VERSION ""

NS_ :

BS_:

BU_:

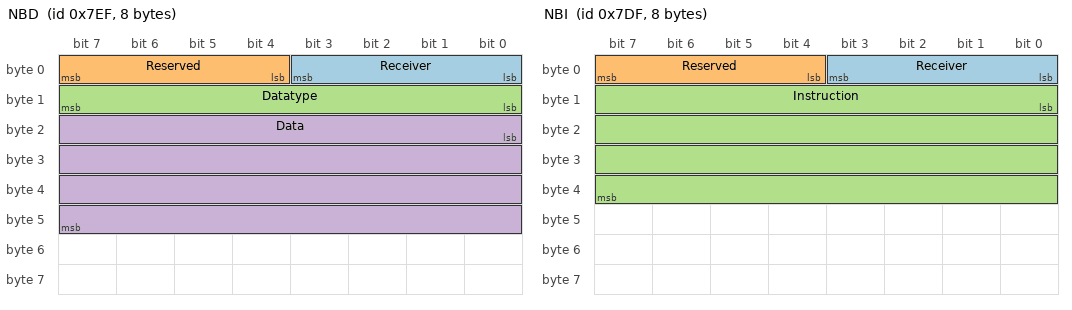
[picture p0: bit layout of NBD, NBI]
BO_ 2031 NBD: 8 Broadcast
	SG_ Receiver : 0|4@1+ (1,0) [0|0] "" Broadcast
	SG_ Reserved : 4|4@1+ (1,0) [0|0] "" Broadcast
	SG_ Datatype : 8|8@1+ (1,0) [0|0] "" Broadcast
	SG_ Data : 16|32@1+ (1,0) [0|0] "" Vector__XXX

BO_ 2015 NBI: 8 Broadcast
	SG_ Receiver : 0|4@1+ (1,0) [0|0] "" Broadcast
	SG_ Reserved : 4|4@1+ (1,0) [0|0] "" Broadcast
	SG_ Instruction : 8|32@1+ (1,0) [0|0] "" Broadcast

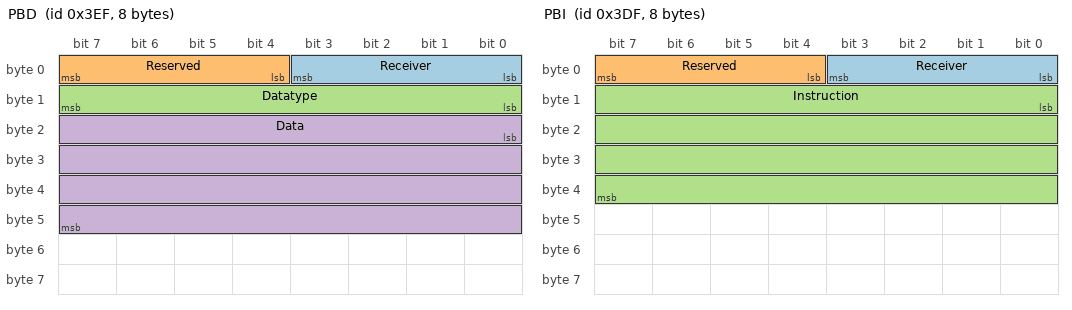
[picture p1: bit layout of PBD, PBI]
BO_ 1007 PBD: 8 Broadcast
	SG_ Receiver : 0|4@1+ (1,0) [0|0] "" Broadcast
	SG_ Reserved : 4|4@1+ (1,0) [0|0] "" Broadcast
	SG_ Datatype : 8|8@1+ (1,0) [0|0] "" Broadcast
	SG_ Data : 16|32@1+ (1,0) [0|0] "" Vector__XXX

BO_ 991 PBI: 8 Broadcast
	SG_ Receiver : 0|4@1+ (1,0) [0|0] "" Broadcast
	SG_ Reserved : 4|4@1+ (1,0) [0|0] "" Broadcast
	SG_ Instruction : 8|32@1+ (1,0) [0|0] "" Broadcast

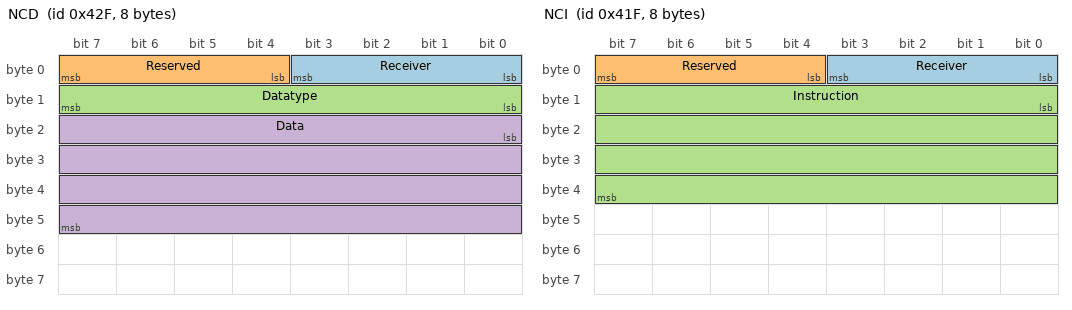
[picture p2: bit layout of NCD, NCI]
BO_ 1071 NCD: 8 CockpitECU
	SG_ Receiver : 0|4@1+ (1,0) [0|0] "" CockpitECU
	SG_ Reserved : 4|4@1+ (1,0) [0|0] "" CockpitECU
	SG_ Datatype : 8|8@1+ (1,0) [0|0] "" CockpitECU
	SG_ Data : 16|32@1+ (1,0) [0|0] "" Vector__XXX

BO_ 1055 NCI: 8 CockpitECU
	SG_ Receiver : 0|4@1+ (1,0) [0|0] "" CockpitECU
	SG_ Reserved : 4|4@1+ (1,0) [0|0] "" CockpitECU
	SG_ Instruction : 8|32@1+ (1,0) [0|0] "" CockpitECU

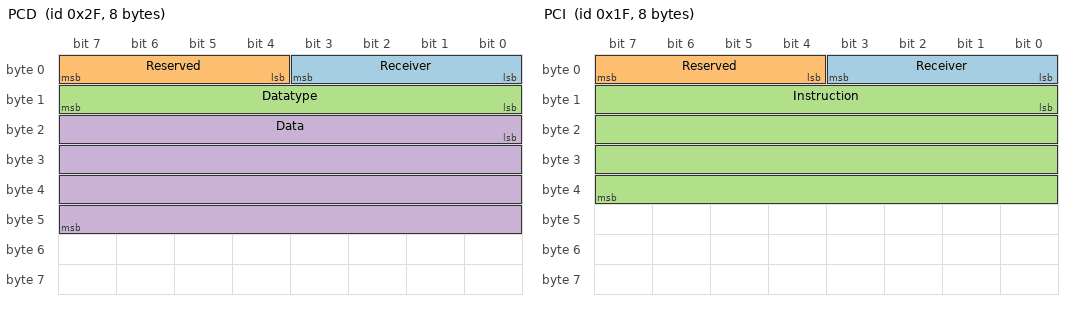
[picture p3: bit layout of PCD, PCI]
BO_ 47 PCD: 8 CockpitECU
	SG_ Receiver : 0|4@1+ (1,0) [0|0] "" CockpitECU
	SG_ Reserved : 4|4@1+ (1,0) [0|0] "" CockpitECU
	SG_ Datatype : 8|8@1+ (1,0) [0|0] "" CockpitECU
	SG_ Data : 16|32@1+ (1,0) [0|0] "" Vector__XXX

BO_ 31 PCI: 8 CockpitECU
	SG_ Receiver : 0|4@1+ (1,0) [0|0] "" CockpitECU
	SG_ Reserved : 4|4@1+ (1,0) [0|0] "" CockpitECU
	SG_ Instruction : 8|32@1+ (1,0) [0|0] "" CockpitECU

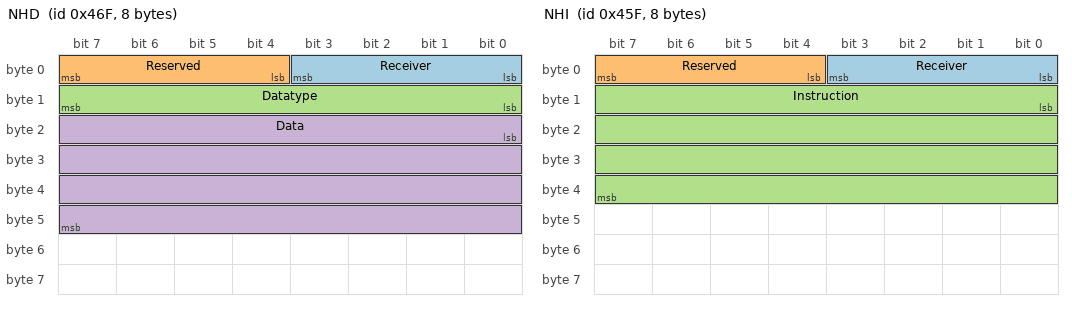
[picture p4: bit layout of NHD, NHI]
BO_ 1135 NHD: 8 HydrogenECU
	SG_ Receiver : 0|4@1+ (1,0) [0|0] "" HydrogenECU
	SG_ Reserved : 4|4@1+ (1,0) [0|0] "" HydrogenECU
	SG_ Datatype : 8|8@1+ (1,0) [0|0] "" HydrogenECU
	SG_ Data : 16|32@1+ (1,0) [0|0] "" Vector__XXX

BO_ 1119 NHI: 8 HydrogenECU
	SG_ Receiver : 0|4@1+ (1,0) [0|0] "" HydrogenECU
	SG_ Reserved : 4|4@1+ (1,0) [0|0] "" HydrogenECU
	SG_ Instruction : 8|32@1+ (1,0) [0|0] "" HydrogenECU

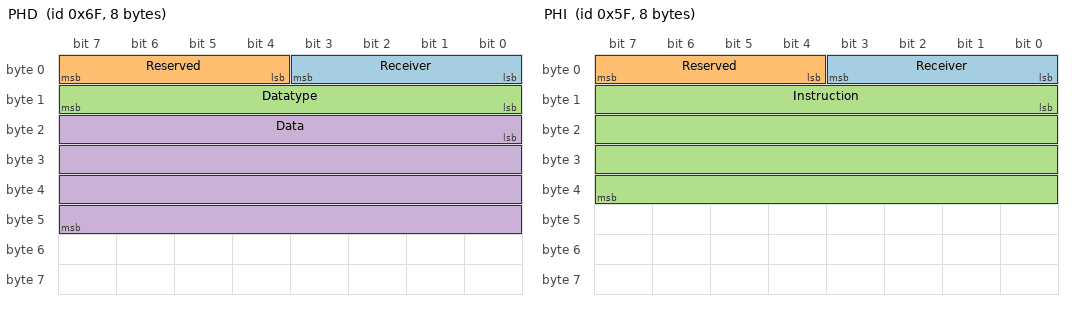
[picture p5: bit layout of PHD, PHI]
BO_ 111 PHD: 8 HydrogenECU
	SG_ Receiver : 0|4@1+ (1,0) [0|0] "" HydrogenECU
	SG_ Reserved : 4|4@1+ (1,0) [0|0] "" HydrogenECU
	SG_ Datatype : 8|8@1+ (1,0) [0|0] "" HydrogenECU
	SG_ Data : 16|32@1+ (1,0) [0|0] "" Vector__XXX

BO_ 95 PHI: 8 HydrogenECU
	SG_ Receiver : 0|4@1+ (1,0) [0|0] "" HydrogenECU
	SG_ Reserved : 4|4@1+ (1,0) [0|0] "" HydrogenECU
	SG_ Instruction : 8|32@1+ (1,0) [0|0] "" HydrogenECU

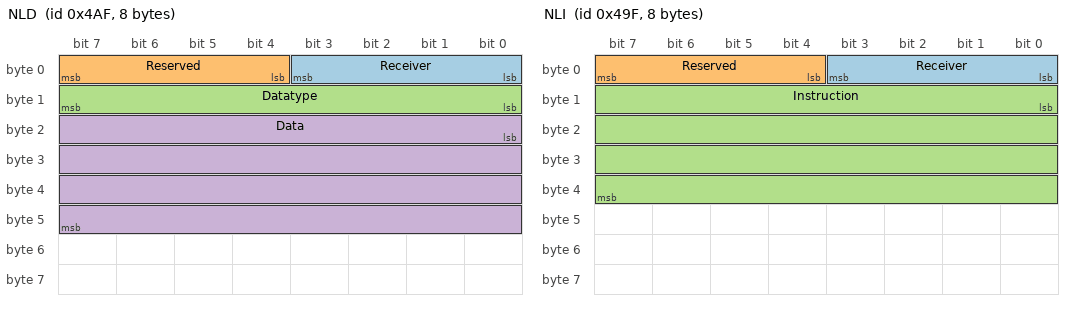
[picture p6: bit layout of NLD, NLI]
BO_ 1199 NLD: 8 LowPowerECU
	SG_ Receiver : 0|4@1+ (1,0) [0|0] "" LowPowerECU
	SG_ Reserved : 4|4@1+ (1,0) [0|0] "" LowPowerECU
	SG_ Datatype : 8|8@1+ (1,0) [0|0] "" LowPowerECU
	SG_ Data : 16|32@1+ (1,0) [0|0] "" Vector__XXX

BO_ 1183 NLI: 8 LowPowerECU
	SG_ Receiver : 0|4@1+ (1,0) [0|0] "" LowPowerECU
	SG_ Reserved : 4|4@1+ (1,0) [0|0] "" LowPowerECU
	SG_ Instruction : 8|32@1+ (1,0) [0|0] "" LowPowerECU

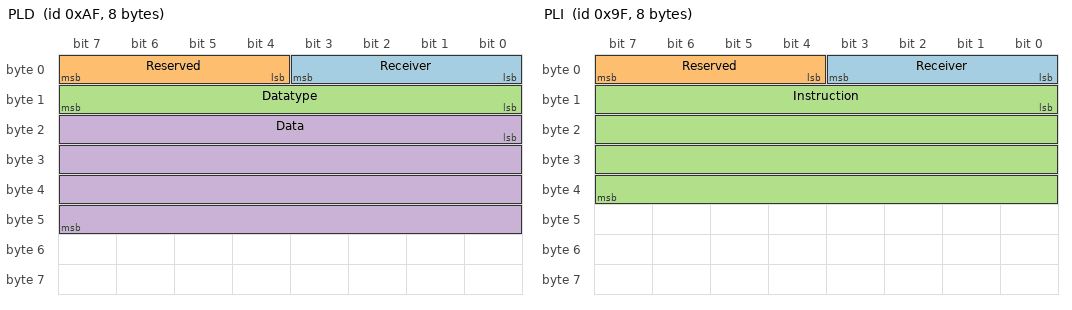
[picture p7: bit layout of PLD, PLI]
BO_ 175 PLD: 8 LowPowerECU
	SG_ Receiver : 0|4@1+ (1,0) [0|0] "" LowPowerECU
	SG_ Reserved : 4|4@1+ (1,0) [0|0] "" LowPowerECU
	SG_ Datatype : 8|8@1+ (1,0) [0|0] "" LowPowerECU
	SG_ Data : 16|32@1+ (1,0) [0|0] "" Vector__XXX

BO_ 159 PLI: 8 LowPowerECU
	SG_ Receiver : 0|4@1+ (1,0) [0|0] "" LowPowerECU
	SG_ Reserved : 4|4@1+ (1,0) [0|0] "" LowPowerECU
	SG_ Instruction : 8|32@1+ (1,0) [0|0] "" LowPowerECU

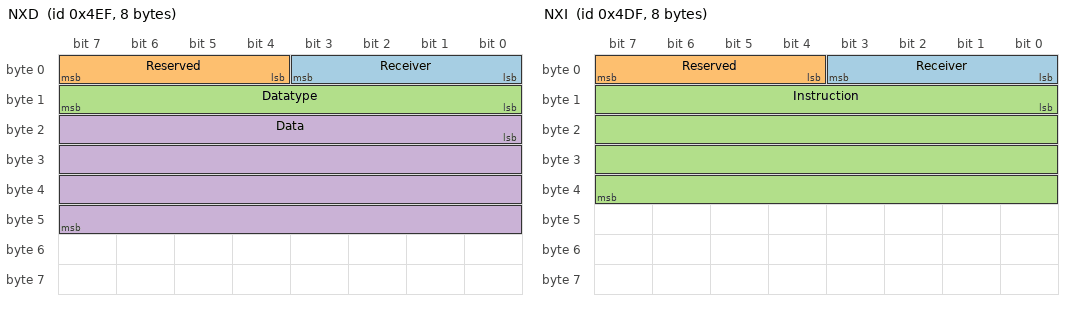
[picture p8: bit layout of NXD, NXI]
BO_ 1263 NXD: 8 HighPowerECU
	SG_ Receiver : 0|4@1+ (1,0) [0|0] "" HighPowerECU
	SG_ Reserved : 4|4@1+ (1,0) [0|0] "" HighPowerECU
	SG_ Datatype : 8|8@1+ (1,0) [0|0] "" HighPowerECU
	SG_ Data : 16|32@1+ (1,0) [0|0] "" Vector__XXX

BO_ 1247 NXI: 8 HighPowerECU
	SG_ Receiver : 0|4@1+ (1,0) [0|0] "" HighPowerECU
	SG_ Reserved : 4|4@1+ (1,0) [0|0] "" HighPowerECU
	SG_ Instruction : 8|32@1+ (1,0) [0|0] "" HighPowerECU

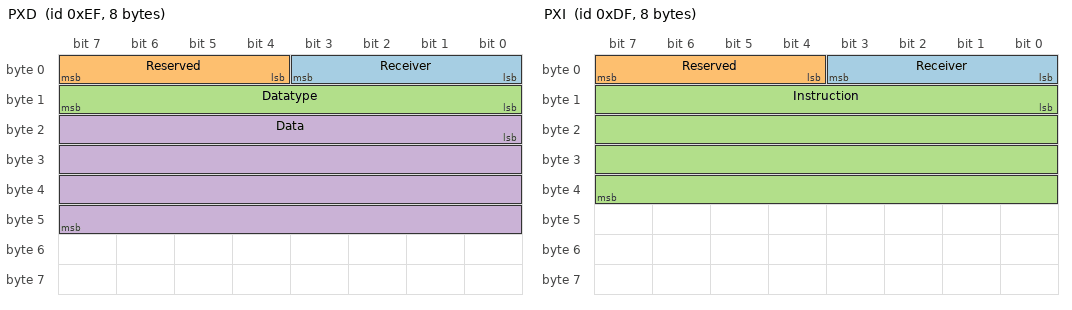
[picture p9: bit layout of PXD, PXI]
BO_ 239 PXD: 8 HighPowerECU
	SG_ Receiver : 0|4@1+ (1,0) [0|0] "" HighPowerECU
	SG_ Reserved : 4|4@1+ (1,0) [0|0] "" HighPowerECU
	SG_ Datatype : 8|8@1+ (1,0) [0|0] "" HighPowerECU
	SG_ Data : 16|32@1+ (1,0) [0|0] "" Vector__XXX

BO_ 223 PXI: 8 HighPowerECU
	SG_ Receiver : 0|4@1+ (1,0) [0|0] "" HighPowerECU
	SG_ Reserved : 4|4@1+ (1,0) [0|0] "" HighPowerECU
	SG_ Instruction : 8|32@1+ (1,0) [0|0] "" HighPowerECU

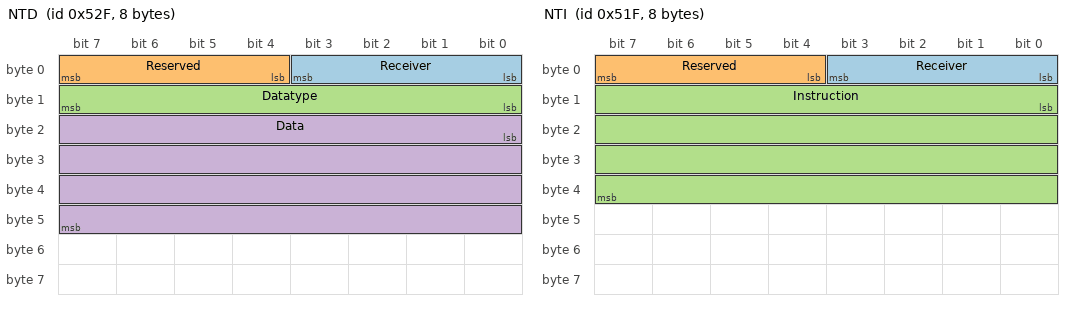
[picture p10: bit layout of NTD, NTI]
BO_ 1327 NTD: 8 TelemetryECU
	SG_ Receiver : 0|4@1+ (1,0) [0|0] "" TelemetryECU
	SG_ Reserved : 4|4@1+ (1,0) [0|0] "" TelemetryECU
	SG_ Datatype : 8|8@1+ (1,0) [0|0] "" TelemetryECU
	SG_ Data : 16|32@1+ (1,0) [0|0] "" Vector__XXX

BO_ 1311 NTI: 8 TelemetryECU
	SG_ Receiver : 0|4@1+ (1,0) [0|0] "" TelemetryECU
	SG_ Reserved : 4|4@1+ (1,0) [0|0] "" TelemetryECU
	SG_ Instruction : 8|32@1+ (1,0) [0|0] "" TelemetryECU

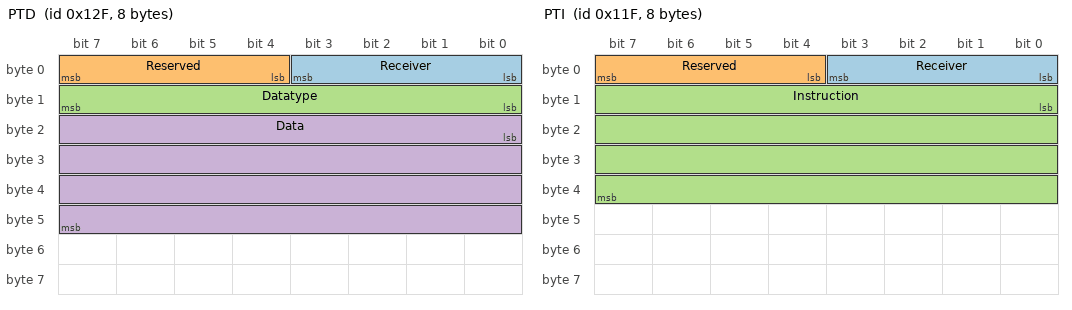
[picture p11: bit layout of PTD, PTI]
BO_ 303 PTD: 8 TelemetryECU
	SG_ Receiver : 0|4@1+ (1,0) [0|0] "" TelemetryECU
	SG_ Reserved : 4|4@1+ (1,0) [0|0] "" TelemetryECU
	SG_ Datatype : 8|8@1+ (1,0) [0|0] "" TelemetryECU
	SG_ Data : 16|32@1+ (1,0) [0|0] "" Vector__XXX

BO_ 287 PTI: 8 TelemetryECU
	SG_ Receiver : 0|4@1+ (1,0) [0|0] "" TelemetryECU
	SG_ Reserved : 4|4@1+ (1,0) [0|0] "" TelemetryECU
	SG_ Instruction : 8|32@1+ (1,0) [0|0] "" TelemetryECU

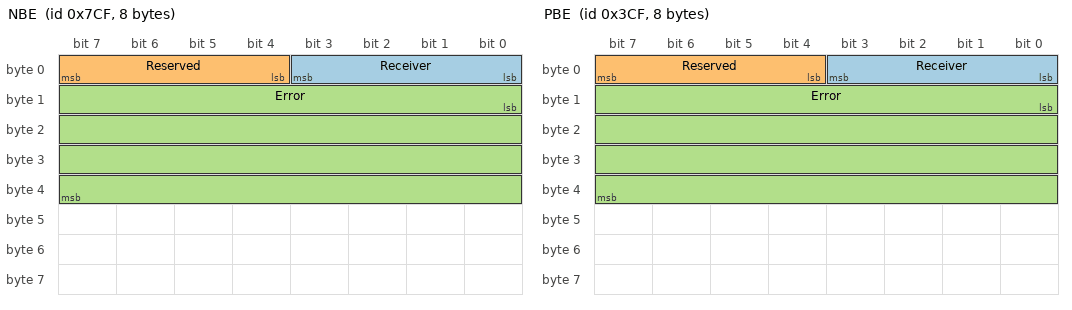
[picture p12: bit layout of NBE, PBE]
BO_ 1999 NBE: 8 Broadcast
	SG_ Receiver : 0|4@1+ (1,0) [0|0] "" Broadcast
	SG_ Reserved : 4|4@1+ (1,0) [0|0] "" Broadcast
	SG_ Error : 8|32@1+ (1,0) [0|0] "" Broadcast

BO_ 975 PBE: 8 Broadcast
	SG_ Receiver : 0|4@1+ (1,0) [0|0] "" Broadcast
	SG_ Reserved : 4|4@1+ (1,0) [0|0] "" Broadcast
	SG_ Error : 8|32@1+ (1,0) [0|0] "" Broadcast

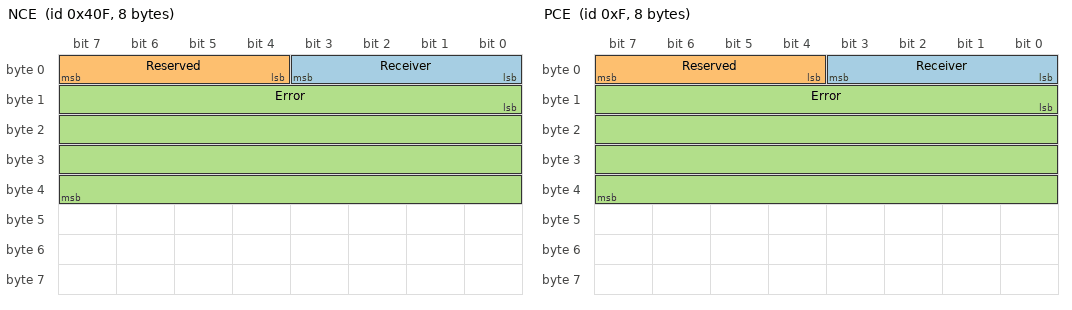
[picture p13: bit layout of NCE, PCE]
BO_ 1039 NCE: 8 CockpitECU
	SG_ Receiver : 0|4@1+ (1,0) [0|0] "" CockpitECU
	SG_ Reserved : 4|4@1+ (1,0) [0|0] "" CockpitECU
	SG_ Error : 8|32@1+ (1,0) [0|0] "" CockpitECU

BO_ 15 PCE: 8 CockpitECU
	SG_ Receiver : 0|4@1+ (1,0) [0|0] "" CockpitECU
	SG_ Reserved : 4|4@1+ (1,0) [0|0] "" CockpitECU
	SG_ Error : 8|32@1+ (1,0) [0|0] "" CockpitECU

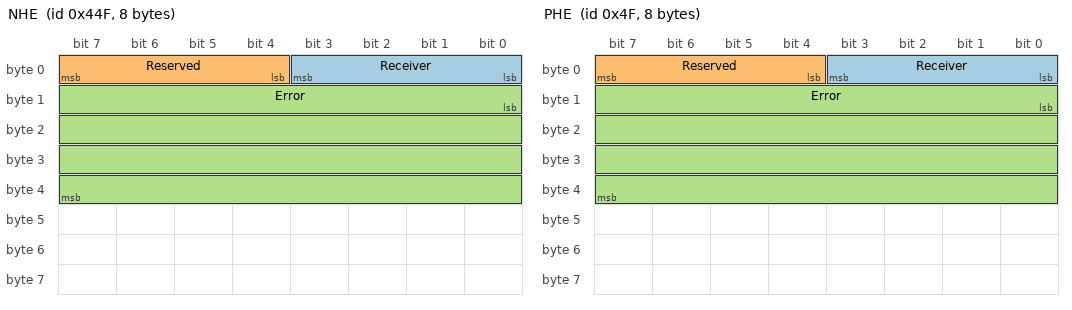
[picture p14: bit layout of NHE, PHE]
BO_ 1103 NHE: 8 HydrogenECU
	SG_ Receiver : 0|4@1+ (1,0) [0|0] "" HydrogenECU
	SG_ Reserved : 4|4@1+ (1,0) [0|0] "" HydrogenECU
	SG_ Error : 8|32@1+ (1,0) [0|0] "" HydrogenECU

BO_ 79 PHE: 8 HydrogenECU
	SG_ Receiver : 0|4@1+ (1,0) [0|0] "" HydrogenECU
	SG_ Reserved : 4|4@1+ (1,0) [0|0] "" HydrogenECU
	SG_ Error : 8|32@1+ (1,0) [0|0] "" HydrogenECU

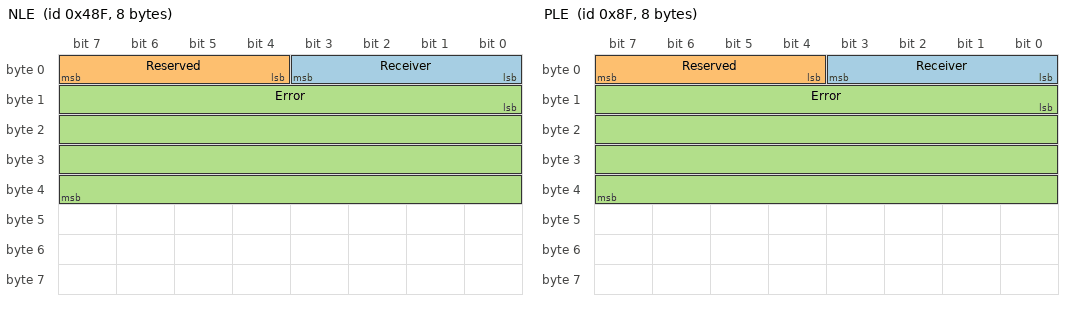
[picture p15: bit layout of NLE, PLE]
BO_ 1167 NLE: 8 LowPowerECU
	SG_ Receiver : 0|4@1+ (1,0) [0|0] "" LowPowerECU
	SG_ Reserved : 4|4@1+ (1,0) [0|0] "" LowPowerECU
	SG_ Error : 8|32@1+ (1,0) [0|0] "" LowPowerECU

BO_ 143 PLE: 8 LowPowerECU
	SG_ Receiver : 0|4@1+ (1,0) [0|0] "" LowPowerECU
	SG_ Reserved : 4|4@1+ (1,0) [0|0] "" LowPowerECU
	SG_ Error : 8|32@1+ (1,0) [0|0] "" LowPowerECU

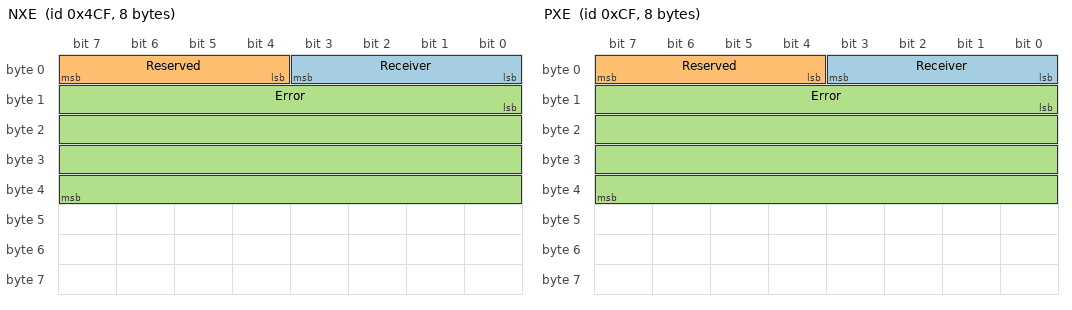
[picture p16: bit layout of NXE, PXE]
BO_ 1231 NXE: 8 HighPowerECU
	SG_ Receiver : 0|4@1+ (1,0) [0|0] "" HighPowerECU
	SG_ Reserved : 4|4@1+ (1,0) [0|0] "" HighPowerECU
	SG_ Error : 8|32@1+ (1,0) [0|0] "" HighPowerECU

BO_ 207 PXE: 8 HighPowerECU
	SG_ Receiver : 0|4@1+ (1,0) [0|0] "" HighPowerECU
	SG_ Reserved : 4|4@1+ (1,0) [0|0] "" HighPowerECU
	SG_ Error : 8|32@1+ (1,0) [0|0] "" HighPowerECU

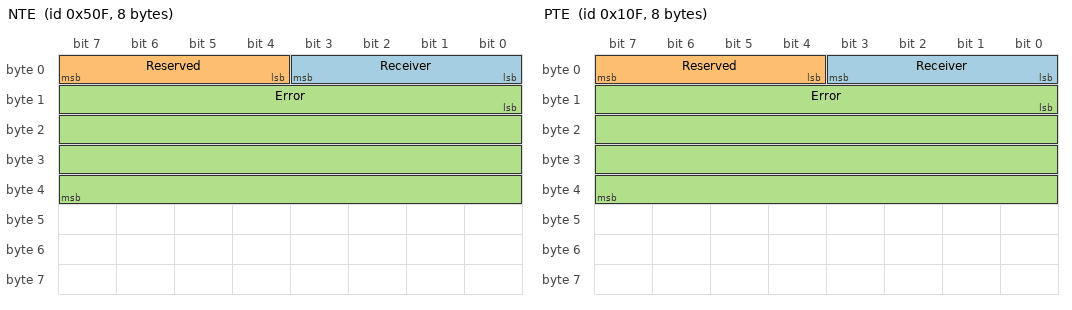
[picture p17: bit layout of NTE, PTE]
BO_ 1295 NTE: 8 TelemetryECU
	SG_ Receiver : 0|4@1+ (1,0) [0|0] "" TelemetryECU
	SG_ Reserved : 4|4@1+ (1,0) [0|0] "" TelemetryECU
	SG_ Error : 8|32@1+ (1,0) [0|0] "" TelemetryECU

BO_ 271 PTE: 8 TelemetryECU
	SG_ Receiver : 0|4@1+ (1,0) [0|0] "" TelemetryECU
	SG_ Reserved : 4|4@1+ (1,0) [0|0] "" TelemetryECU
	SG_ Error : 8|32@1+ (1,0) [0|0] "" TelemetryECU

CM_ BO_ 2031 "Low Priority, Broadcast, Data";
CM_ BO_ 2015 "Low Priority, Broadcast, Data";
CM_ BO_ 31 "High Priority, Cockpit, Instruction";
CM_ BO_ 47 "High Priority, Cockpit, Data";
CM_ BO_ 95 "High Priority, Hydrogen, Instruction";
CM_ BO_ 111 "High Priority, Hydrogen, Data";
CM_ BO_ 159 "High Priority, Low Power, Instruction";
CM_ BO_ 175 "High Priority, Low Power, Data";
CM_ BO_ 223 "High Priority, High Power, Instruction";
CM_ BO_ 239 "High Priority, High Power, Data";
CM_ BO_ 287 "High Priority, Telemetry, Instruction";
CM_ BO_ 303 "High Priority, Telemetry, Data";
CM_ BO_ 991 "High Priority, Broadcast, Instruction";
CM_ BO_ 1007 "High Priority, Broadcast, Data";
CM_ BO_ 1055 "Low Priority, Cockpit, Instruction";
CM_ BO_ 1071 "Low Priority, Cockpit, Data";
CM_ BO_ 1119 "Low Priority, Hydrogen, Instruction";
CM_ BO_ 1135 "Low Priority, Hydrogen, Data";
CM_ BO_ 1183 "Low Priority, Low Power, Instruction";
CM_ BO_ 1199 "Low Priority, Low Power, Data";
CM_ BO_ 1247 "Low Priority, High Power, Instruction";
CM_ BO_ 1263 "Low Priority, High Power, Data";
CM_ BO_ 1311 "Low Priority, Telemetry, Instruction";
CM_ BO_ 1327 "Low Priority, Telemetry, Data";
CM_ BO_ 1999 "Low Priority, Broadcast, Error";
CM_ BO_ 975 "High Priority, Broadcast, Error";
CM_ BO_ 1039 "Low Priority, Cockpit, Error";
CM_ BO_ 15 "High Priority, Cockpit, Error";
CM_ BO_ 1103 "Low Priority, Hydrogen, Error";
CM_ BO_ 79 "High Priority, Hydrogen, Error";
CM_ BO_ 1167 "Low Priority, Low Power, Error";
CM_ BO_ 143 "High Priority, Low Power, Error";
CM_ BO_ 1231 "Low Priority, High Power, Error";
CM_ BO_ 207 "High Priority, High Power, Error";
CM_ BO_ 1295 "Low Priority, Telemetry, Error";
CM_ BO_ 271 "High Priority, Telemetry, Error";
BA_DEF_ BO_  "VFrameFormat" ENUM  "StandardCAN","ExtendedCAN","reserved","J1939PG";
BA_DEF_  "DatabaseVersion" STRING ;
BA_DEF_  "BusType" STRING ;
BA_DEF_  "ProtocolType" STRING ;
BA_DEF_  "DatabaseCompiler" STRING ;
BA_DEF_DEF_  "VFrameFormat" "J1939PG";
BA_DEF_DEF_  "DatabaseVersion" "DEMO PLUS";
BA_DEF_DEF_  "BusType" "";
BA_DEF_DEF_  "ProtocolType" "";
BA_DEF_DEF_  "DatabaseCompiler" "";
BA_ "BusType" "CAN";
BA_ "DatabaseCompiler" "CSS ELECTRONICS (WWW.CSSELECTRONICS.COM)";
BA_ "DatabaseVersion" "1.0.0";
